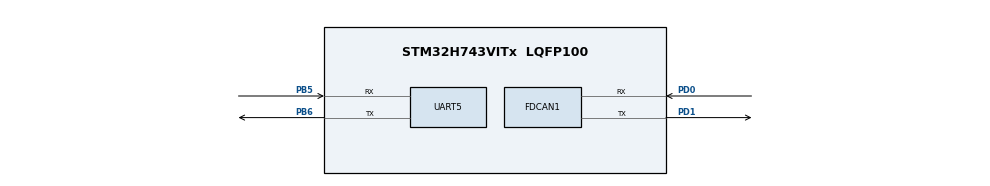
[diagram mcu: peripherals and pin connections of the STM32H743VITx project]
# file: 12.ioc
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CORTEX_M7.default_mode_Activation=1
Dma.Request0=UART5_RX
Dma.Request1=UART5_TX
Dma.UART5_RX.0.Direction=DMA_PERIPH_TO_MEMORY
Dma.UART5_RX.0.EventEnable=DISABLE
Dma.UART5_RX.0.FIFOMode=DMA_FIFOMODE_DISABLE
Dma.UART5_RX.0.Instance=DMA2_Stream0
Dma.UART5_RX.0.MemDataAlignment=DMA_MDATAALIGN_BYTE
Dma.UART5_RX.0.MemInc=DMA_MINC_ENABLE
Dma.UART5_RX.0.Mode=DMA_CIRCULAR
Dma.UART5_RX.0.PeriphDataAlignment=DMA_PDATAALIGN_BYTE
Dma.UART5_RX.0.PeriphInc=DMA_PINC_DISABLE
Dma.UART5_RX.0.Polarity=HAL_DMAMUX_REQ_GEN_RISING
Dma.UART5_RX.0.Priority=DMA_PRIORITY_LOW
Dma.UART5_RX.0.RequestNumber=1
Dma.UART5_RX.0.SignalID=NONE
Dma.UART5_RX.0.SyncEnable=DISABLE
Dma.UART5_RX.0.SyncPolarity=HAL_DMAMUX_SYNC_NO_EVENT
Dma.UART5_RX.0.SyncRequestNumber=1
Dma.UART5_RX.0.SyncSignalID=NONE
Dma.UART5_TX.1.Direction=DMA_MEMORY_TO_PERIPH
Dma.UART5_TX.1.EventEnable=DISABLE
Dma.UART5_TX.1.FIFOMode=DMA_FIFOMODE_DISABLE
Dma.UART5_TX.1.Instance=DMA2_Stream1
Dma.UART5_TX.1.MemDataAlignment=DMA_MDATAALIGN_BYTE
Dma.UART5_TX.1.MemInc=DMA_MINC_ENABLE
Dma.UART5_TX.1.Mode=DMA_NORMAL
Dma.UART5_TX.1.PeriphDataAlignment=DMA_PDATAALIGN_BYTE
Dma.UART5_TX.1.PeriphInc=DMA_PINC_DISABLE
Dma.UART5_TX.1.Polarity=HAL_DMAMUX_REQ_GEN_RISING
Dma.UART5_TX.1.Priority=DMA_PRIORITY_LOW
Dma.UART5_TX.1.RequestNumber=1
Dma.UART5_TX.1.SignalID=NONE
Dma.UART5_TX.1.SyncEnable=DISABLE
Dma.UART5_TX.1.SyncPolarity=HAL_DMAMUX_SYNC_NO_EVENT
Dma.UART5_TX.1.SyncRequestNumber=1
Dma.UART5_TX.1.SyncSignalID=NONE
FDCAN1.AutoRetransmission=ENABLE
FDCAN1.CalculateBaudRateNominal=500000
FDCAN1.CalculateTimeBitNominal=2000
FDCAN1.CalculateTimeQuantumNominal=50.0
FDCAN1.DataSyncJumpWidth=8
FDCAN1.DataTimeSeg1=31
FDCAN1.DataTimeSeg2=8
FDCAN1.ExtFiltersNbr=1
FDCAN1.NominalPrescaler=1
FDCAN1.NominalSyncJumpWidth=8
FDCAN1.NominalTimeSeg1=31
FDCAN1.NominalTimeSeg2=8
FDCAN1.ProtocolException=ENABLE
FDCAN1.RxBuffersNbr=1
FDCAN1.RxFifo0ElmtsNbr=1
FDCAN1.RxFifo1ElmtsNbr=1
FDCAN1.StdFiltersNbr=1
FDCAN1.TransmitPause=ENABLE
FDCAN1.TxBuffersNbr=1
FDCAN1.TxEventsNbr=1
FDCAN1.TxFifoQueueElmtsNbr=32
Mcu.Family=STM32H7
Mcu.Name=STM32H743VITx
Mcu.Package=LQFP100
NVIC.DMA2_Stream0_IRQn=true\:0\:0\:false\:false\:true\:false\:true\:true
NVIC.DMA2_Stream1_IRQn=true\:0\:0\:false\:false\:true\:false\:true\:true
NVIC.FDCAN1_IT0_IRQn=true\:0\:0\:false\:false\:true\:true\:true\:true
NVIC.FDCAN1_IT1_IRQn=true\:0\:0\:false\:false\:true\:true\:true\:true
NVIC.FDCAN_CAL_IRQn=true\:0\:0\:false\:false\:true\:true\:true\:true
NVIC.PriorityGroup=NVIC_PRIORITYGROUP_4
NVIC.UART5_IRQn=true\:0\:0\:false\:false\:true\:true\:true\:true
PB5.Mode=Asynchronous
PB5.Signal=UART5_RX
PB6.Mode=Asynchronous
PB6.Signal=UART5_TX
PD0.Mode=FDCAN_Activate
PD0.Signal=FDCAN1_RX
PD1.Mode=FDCAN_Activate
PD1.Signal=FDCAN1_TX
PH0-OSC_IN\ (PH0).Mode=HSE-External-Clock-Source
PH0-OSC_IN\ (PH0).Signal=RCC_OSC_IN
ProjectManager.HeapSize=0x200
ProjectManager.StackSize=0x400
ProjectManager.TargetToolchain=MDK-ARM V5.32
RCC.ADCFreq_Value=129000000
RCC.APB1Freq_Value=40000000
RCC.APB2Freq_Value=80000000
RCC.APB3Freq_Value=80000000
RCC.APB4Freq_Value=80000000
RCC.CortexFreq_Value=80000000
RCC.D2PPRE1=RCC_APB1_DIV2
RCC.DIVM1=4
RCC.DIVN1=10
RCC.DIVQ1=8
RCC.HCLKFreq_Value=80000000
RCC.PLL2FRACN=0
RCC.PLL3FRACN=0
RCC.PLLFRACN=0
RCC.SYSCLKFreq_VALUE=80000000
RCC.SYSCLKSource=RCC_SYSCLKSOURCE_PLLCLK
RCC.USBFreq_Value=20000000
VP_MEMORYMAP_VS_MEMORYMAP.Mode=CurAppReg
board=custom

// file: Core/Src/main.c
/* USER CODE BEGIN Header */
/**
  ******************************************************************************
  * @file           : main.c
  * @brief          : Main program body
  ******************************************************************************
  * @attention
  *
  * Copyright (c) 2025 STMicroelectronics.
  * All rights reserved.
  *
  * This software is licensed under terms that can be found in the LICENSE file
  * in the root directory of this software component.
  * If no LICENSE file comes with this software, it is provided AS-IS.
  *
  ******************************************************************************
  */
/* USER CODE END Header */
#include "main.h"

FDCAN_HandleTypeDef hfdcan1;

UART_HandleTypeDef huart5;
DMA_HandleTypeDef hdma_uart5_rx;
DMA_HandleTypeDef hdma_uart5_tx;

void SystemClock_Config(void);
static void MPU_Config(void);
static void MX_GPIO_Init(void);
static void MX_DMA_Init(void);
static void MX_UART5_Init(void);
static void MX_FDCAN1_Init(void);

/* USER CODE BEGIN 0 */
uint8_t aTxBuffer[10]={'1','2','3','4','5','6','7','8','9','0'};
/* USER CODE END 0 */

int main(void)
{

  /* MPU Configuration--------------------------------------------------------*/
  MPU_Config();

  /* MCU Configuration--------------------------------------------------------*/

  /* Reset of all peripherals, Initializes the Flash interface and the Systick. */
  HAL_Init();

  /* Configure the system clock */
  SystemClock_Config();

  /* Initialize all configured peripherals */
  MX_GPIO_Init();
  MX_DMA_Init();
  MX_UART5_Init();
  MX_FDCAN1_Init();

  /* Infinite loop */
  while (1)
  {

    /* USER CODE BEGIN 3 */
		HAL_UART_Transmit_DMA(&huart5, (uint8_t *)&aTxBuffer[3], 1);
		HAL_Delay(1000);
	}
  /* USER CODE END 3 */
}

void SystemClock_Config(void)
{
  RCC_OscInitTypeDef RCC_OscInitStruct = {0};
  RCC_ClkInitTypeDef RCC_ClkInitStruct = {0};

  /** Supply configuration update enable
  */
  HAL_PWREx_ConfigSupply(PWR_LDO_SUPPLY);

  /** Configure the main internal regulator output voltage
  */
  __HAL_PWR_VOLTAGESCALING_CONFIG(PWR_REGULATOR_VOLTAGE_SCALE3);

  while(!__HAL_PWR_GET_FLAG(PWR_FLAG_VOSRDY)) {}

  /** Initializes the RCC Oscillators according to the specified parameters
  * in the RCC_OscInitTypeDef structure.
  */
  RCC_OscInitStruct.OscillatorType = RCC_OSCILLATORTYPE_HSI;
  RCC_OscInitStruct.HSIState = RCC_HSI_DIV1;
  RCC_OscInitStruct.HSICalibrationValue = RCC_HSICALIBRATION_DEFAULT;
  RCC_OscInitStruct.PLL.PLLState = RCC_PLL_ON;
  RCC_OscInitStruct.PLL.PLLSource = RCC_PLLSOURCE_HSI;
  RCC_OscInitStruct.PLL.PLLM = 4;
  RCC_OscInitStruct.PLL.PLLN = 10;
  RCC_OscInitStruct.PLL.PLLP = 2;
  RCC_OscInitStruct.PLL.PLLQ = 8;
  RCC_OscInitStruct.PLL.PLLR = 2;
  RCC_OscInitStruct.PLL.PLLRGE = RCC_PLL1VCIRANGE_3;
  RCC_OscInitStruct.PLL.PLLVCOSEL = RCC_PLL1VCOMEDIUM;
  RCC_OscInitStruct.PLL.PLLFRACN = 0;
  if (HAL_RCC_OscConfig(&RCC_OscInitStruct) != HAL_OK)
  {
    Error_Handler();
  }

  /** Initializes the CPU, AHB and APB buses clocks
  */
  RCC_ClkInitStruct.ClockType = RCC_CLOCKTYPE_HCLK|RCC_CLOCKTYPE_SYSCLK
                              |RCC_CLOCKTYPE_PCLK1|RCC_CLOCKTYPE_PCLK2
                              |RCC_CLOCKTYPE_D3PCLK1|RCC_CLOCKTYPE_D1PCLK1;
  RCC_ClkInitStruct.SYSCLKSource = RCC_SYSCLKSOURCE_PLLCLK;
  RCC_ClkInitStruct.SYSCLKDivider = RCC_SYSCLK_DIV1;
  RCC_ClkInitStruct.AHBCLKDivider = RCC_HCLK_DIV1;
  RCC_ClkInitStruct.APB3CLKDivider = RCC_APB3_DIV1;
  RCC_ClkInitStruct.APB1CLKDivider = RCC_APB1_DIV2;
  RCC_ClkInitStruct.APB2CLKDivider = RCC_APB2_DIV1;
  RCC_ClkInitStruct.APB4CLKDivider = RCC_APB4_DIV1;

  if (HAL_RCC_ClockConfig(&RCC_ClkInitStruct, FLASH_LATENCY_1) != HAL_OK)
  {
    Error_Handler();
  }
}

static void MX_FDCAN1_Init(void)
{

  hfdcan1.Instance = FDCAN1;
  hfdcan1.Init.FrameFormat = FDCAN_FRAME_CLASSIC;
  hfdcan1.Init.Mode = FDCAN_MODE_NORMAL;
  hfdcan1.Init.AutoRetransmission = ENABLE;
  hfdcan1.Init.TransmitPause = ENABLE;
  hfdcan1.Init.ProtocolException = ENABLE;
  hfdcan1.Init.NominalPrescaler = 1;
  hfdcan1.Init.NominalSyncJumpWidth = 8;
  hfdcan1.Init.NominalTimeSeg1 = 31;
  hfdcan1.Init.NominalTimeSeg2 = 8;
  hfdcan1.Init.DataPrescaler = 1;
  hfdcan1.Init.DataSyncJumpWidth = 8;
  hfdcan1.Init.DataTimeSeg1 = 31;
  hfdcan1.Init.DataTimeSeg2 = 8;
  hfdcan1.Init.MessageRAMOffset = 0;
  hfdcan1.Init.StdFiltersNbr = 1;
  hfdcan1.Init.ExtFiltersNbr = 1;
  hfdcan1.Init.RxFifo0ElmtsNbr = 1;
  hfdcan1.Init.RxFifo0ElmtSize = FDCAN_DATA_BYTES_8;
  hfdcan1.Init.RxFifo1ElmtsNbr = 1;
  hfdcan1.Init.RxFifo1ElmtSize = FDCAN_DATA_BYTES_8;
  hfdcan1.Init.RxBuffersNbr = 1;
  hfdcan1.Init.RxBufferSize = FDCAN_DATA_BYTES_8;
  hfdcan1.Init.TxEventsNbr = 1;
  hfdcan1.Init.TxBuffersNbr = 1;
  hfdcan1.Init.TxFifoQueueElmtsNbr = 32;
  hfdcan1.Init.TxFifoQueueMode = FDCAN_TX_FIFO_OPERATION;
  hfdcan1.Init.TxElmtSize = FDCAN_DATA_BYTES_8;
  if (HAL_FDCAN_Init(&hfdcan1) != HAL_OK)
  {
    Error_Handler();
  }

}

static void MX_UART5_Init(void)
{

  huart5.Instance = UART5;
  huart5.Init.BaudRate = 115200;
  huart5.Init.WordLength = UART_WORDLENGTH_8B;
  huart5.Init.StopBits = UART_STOPBITS_1;
  huart5.Init.Parity = UART_PARITY_NONE;
  huart5.Init.Mode = UART_MODE_TX_RX;
  huart5.Init.HwFlowCtl = UART_HWCONTROL_NONE;
  huart5.Init.OverSampling = UART_OVERSAMPLING_16;
  huart5.Init.OneBitSampling = UART_ONE_BIT_SAMPLE_DISABLE;
  huart5.Init.ClockPrescaler = UART_PRESCALER_DIV1;
  huart5.AdvancedInit.AdvFeatureInit = UART_ADVFEATURE_NO_INIT;
  if (HAL_UART_Init(&huart5) != HAL_OK)
  {
    Error_Handler();
  }
  if (HAL_UARTEx_SetTxFifoThreshold(&huart5, UART_TXFIFO_THRESHOLD_1_8) != HAL_OK)
  {
    Error_Handler();
  }
  if (HAL_UARTEx_SetRxFifoThreshold(&huart5, UART_RXFIFO_THRESHOLD_1_8) != HAL_OK)
  {
    Error_Handler();
  }
  if (HAL_UARTEx_DisableFifoMode(&huart5) != HAL_OK)
  {
    Error_Handler();
  }

}

static void MX_DMA_Init(void)
{

  /* DMA controller clock enable */
  __HAL_RCC_DMA2_CLK_ENABLE();

  /* DMA interrupt init */
  /* DMA2_Stream0_IRQn interrupt configuration */
  HAL_NVIC_SetPriority(DMA2_Stream0_IRQn, 0, 0);
  HAL_NVIC_EnableIRQ(DMA2_Stream0_IRQn);
  /* DMA2_Stream1_IRQn interrupt configuration */
  HAL_NVIC_SetPriority(DMA2_Stream1_IRQn, 0, 0);
  HAL_NVIC_EnableIRQ(DMA2_Stream1_IRQn);

}

static void MX_GPIO_Init(void)
{

  /* GPIO Ports Clock Enable */
  __HAL_RCC_GPIOH_CLK_ENABLE();
  __HAL_RCC_GPIOD_CLK_ENABLE();
  __HAL_RCC_GPIOB_CLK_ENABLE();

}

 /* MPU Configuration */

void MPU_Config(void)
{
  MPU_Region_InitTypeDef MPU_InitStruct = {0};

  /* Disables the MPU */
  HAL_MPU_Disable();

  /** Initializes and configures the Region and the memory to be protected
  */
  MPU_InitStruct.Enable = MPU_REGION_ENABLE;
  MPU_InitStruct.Number = MPU_REGION_NUMBER0;
  MPU_InitStruct.BaseAddress = 0x0;
  MPU_InitStruct.Size = MPU_REGION_SIZE_4GB;
  MPU_InitStruct.SubRegionDisable = 0x87;
  MPU_InitStruct.TypeExtField = MPU_TEX_LEVEL0;
  MPU_InitStruct.AccessPermission = MPU_REGION_NO_ACCESS;
  MPU_InitStruct.DisableExec = MPU_INSTRUCTION_ACCESS_DISABLE;
  MPU_InitStruct.IsShareable = MPU_ACCESS_SHAREABLE;
  MPU_InitStruct.IsCacheable = MPU_ACCESS_NOT_CACHEABLE;
  MPU_InitStruct.IsBufferable = MPU_ACCESS_NOT_BUFFERABLE;

  HAL_MPU_ConfigRegion(&MPU_InitStruct);
  /* Enables the MPU */
  HAL_MPU_Enable(MPU_PRIVILEGED_DEFAULT);

}

void Error_Handler(void)
{
  __disable_irq();
  while (1)
  {
  }
}
